/*
 * The MIT License (MIT)
 *
 * Copyright (c) 2015-2019 Erik Moqvist
 *
 * Permission is hereby granted, free of charge, to any person obtaining a copy
 * of this software and associated documentation files (the "Software"), to deal
 * in the Software without restriction, including without limitation the rights
 * to use, copy, modify, merge, publish, distribute, sublicense, and/or sell
 * copies of the Software, and to permit persons to whom the Software is
 * furnished to do so, subject to the following conditions:
 *
 * The above copyright notice and this permission notice shall be included in all
 * copies or substantial portions of the Software.
 *
 * THE SOFTWARE IS PROVIDED "AS IS", WITHOUT WARRANTY OF ANY KIND, EXPRESS OR
 * IMPLIED, INCLUDING BUT NOT LIMITED TO THE WARRANTIES OF MERCHANTABILITY,
 * FITNESS FOR A PARTICULAR PURPOSE AND NONINFRINGEMENT. IN NO EVENT SHALL THE
 * AUTHORS OR COPYRIGHT HOLDERS BE LIABLE FOR ANY CLAIM, DAMAGES OR OTHER
 * LIABILITY, WHETHER IN AN ACTION OF CONTRACT, TORT OR OTHERWISE, ARISING FROM,
 * OUT OF OR IN CONNECTION WITH THE SOFTWARE OR THE USE OR OTHER DEALINGS IN THE
 * SOFTWARE.
 */

VERSION ""

NS_ :

BS_:

BU_: NN123456789012345678901234567890 N12345678901234567890123456_0000 N1234567890123456789012345678901 N12345678901234567890123456_0001

BO_ 9 SS123456789012345678901234587890: 8 Vector__XXX

BO_ 8 SS1234567890123456789012345_0000: 8 Vector__XXX

BO_ 7 SS1234567890123456789012345_0001: 8 Vector__XXX

BO_ 6 SS123456789012345678901234577890: 8 Vector__XXX

BO_ 5 SS123456789012345678901234567890: 8 Vector__XXX

BO_ 4 S1234567890123456789012345678901: 8 Vector__XXX
 SG_ SS123456789012345678901234567890 : 0|8@1- (1,0) [0|0] "" Vector__XXX

BO_ 0 M12345678901234567890123456_0000: 8 Vector__XXX
 SG_ SSS12345678901234567890123456789 : 0|8@1- (1,0) [0|0] "" Vector__XXX

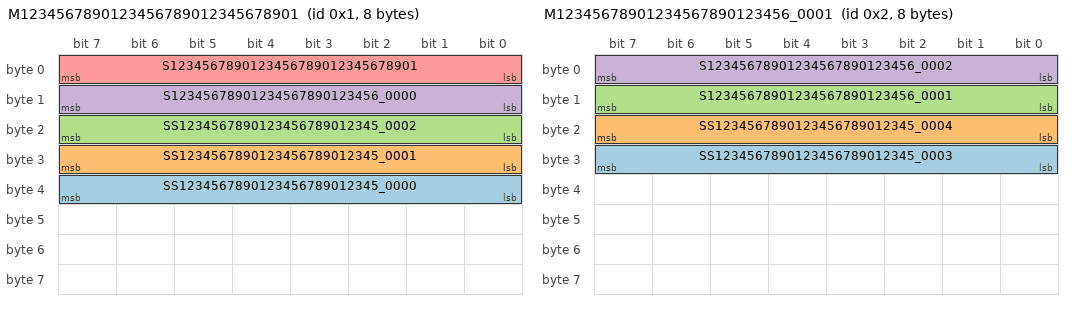
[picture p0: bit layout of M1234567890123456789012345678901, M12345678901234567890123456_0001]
BO_ 1 M1234567890123456789012345678901: 8 N1234567890123456789012345678901
 SG_ SS1234567890123456789012345_0000 : 32|8@1- (1,0) [0|0] "" Vector__XXX
 SG_ SS1234567890123456789012345_0001 : 24|8@1- (1,0) [0|0] "" Vector__XXX
 SG_ SS1234567890123456789012345_0002 : 16|8@1- (1,0) [0|0] ""  N12345678901234567890123456_0000
 SG_ S12345678901234567890123456_0000 : 8|8@1- (1,0) [0|0] "" Vector__XXX
 SG_ S1234567890123456789012345678901 : 0|8@1- (1,0) [0|0] "" Vector__XXX

BO_ 2 M12345678901234567890123456_0001: 8 N12345678901234567890123456_0001
 SG_ SS1234567890123456789012345_0003 : 24|8@1- (1,0) [0|0] "" Vector__XXX
 SG_ SS1234567890123456789012345_0004 : 16|8@1- (1,0) [0|0] "" Vector__XXX
 SG_ S12345678901234567890123456_0001 : 8|8@1- (1,0) [0|0] "" Vector__XXX
 SG_ S12345678901234567890123456_0002 : 0|8@1- (1,0) [0|0] "" Vector__XXX

BO_ 3 MM123456789012345678901234567890: 8 Vector__XXX
 SG_ SSS123456789012345678901234_0000 : 8|8@1- (1,0) [0|0] "" Vector__XXX
 SG_ SS1234567890123456789012345_0005 : 0|8@1- (1,0) [0|0] "" Vector__XXX

EV_ E12345678901234567890123456_0000: 0 [0|0] "" 0 1 DUMMY_NODE_VECTOR0 Vector__XXX;

EV_ E1234567890123456789012345678901: 0 [0|0] "" 0 2 DUMMY_NODE_VECTOR0 Vector__XXX;

BA_DEF_ SG_  "SystemSignalLongSymbol" STRING ;
BA_DEF_ BO_  "SystemMessageLongSymbol" STRING ;
BA_DEF_ BU_  "SystemNodeLongSymbol" STRING ;
BA_DEF_ EV_  "SystemEnvVarLongSymbol" STRING ;
BA_DEF_DEF_  "SystemSignalLongSymbol" "";
BA_DEF_DEF_  "SystemMessageLongSymbol" "";
BA_DEF_DEF_  "SystemNodeLongSymbol" "";
BA_DEF_DEF_  "SystemEnvVarLongSymbol" "";
BA_ "SystemNodeLongSymbol" BU_ NN123456789012345678901234567890 "NN123456789012345678901234567890123";
BA_ "SystemNodeLongSymbol" BU_ N12345678901234567890123456_0000 "N123456789012345678901234567890123";
BA_ "SystemNodeLongSymbol" BU_ N12345678901234567890123456_0001 "N12345678901234567890123456789012";
BA_ "SystemMessageLongSymbol" BO_ 9 "SS12345678901234567890123458789012345";
BA_ "SystemMessageLongSymbol" BO_ 8 "SS1234567890123456789012345778901";
BA_ "SystemMessageLongSymbol" BO_ 7 "SS1234567890123456789012345878901234";
BA_ "SystemMessageLongSymbol" BO_ 5 "SS12345678901234567890123456789012";
BA_ "SystemMessageLongSymbol" BO_ 4 "S12345678901234567890123456789012";
BA_ "SystemMessageLongSymbol" BO_ 0 "M123456789012345678901234567890123";
BA_ "SystemMessageLongSymbol" BO_ 2 "M12345678901234567890123456789012";
BA_ "SystemMessageLongSymbol" BO_ 3 "MM12345678901234567890123456789012";
BA_ "SystemSignalLongSymbol" SG_ 4 SS123456789012345678901234567890 "SS12345678901234567890123456789012";
BA_ "SystemSignalLongSymbol" SG_ 0 SSS12345678901234567890123456789 "SSS12345678901234567890123456789012";
BA_ "SystemSignalLongSymbol" SG_ 1 SS1234567890123456789012345_0000 "SS12345678901234567890123456789012332";
BA_ "SystemSignalLongSymbol" SG_ 1 SS1234567890123456789012345_0001 "SS1234567890123456789012345678901233";
BA_ "SystemSignalLongSymbol" SG_ 1 SS1234567890123456789012345_0002 "SS12345678901234567890123456789012";
BA_ "SystemSignalLongSymbol" SG_ 1 S12345678901234567890123456_0000 "S123456789012345678901234567890123";
BA_ "SystemSignalLongSymbol" SG_ 2 SS1234567890123456789012345_0003 "SS12345678901234567890123456789012dw";
BA_ "SystemSignalLongSymbol" SG_ 2 SS1234567890123456789012345_0004 "SS12345678901234567890123456789012";
BA_ "SystemSignalLongSymbol" SG_ 2 S12345678901234567890123456_0001 "S12345678901234567890123456789012";
BA_ "SystemSignalLongSymbol" SG_ 2 S12345678901234567890123456_0002 "S123456789012345678901234567890123";
BA_ "SystemSignalLongSymbol" SG_ 3 SSS123456789012345678901234_0000 "SSS12345678901234567890123456789012";
BA_ "SystemSignalLongSymbol" SG_ 3 SS1234567890123456789012345_0005 "SS1234567890123456789012345678901233";
BA_ "SystemEnvVarLongSymbol" EV_ E12345678901234567890123456_0000 "E12345678901234567890123456789012";
